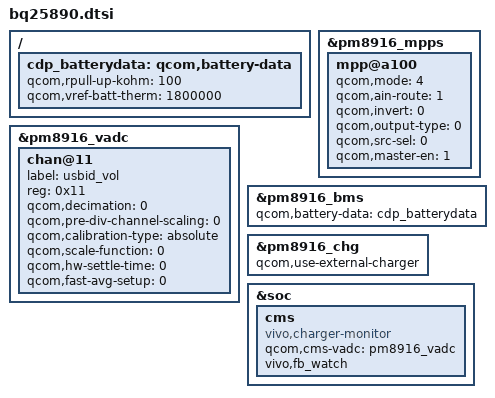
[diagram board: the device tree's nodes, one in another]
/* Copyright (c) 2014, The Linux Foundation. All rights reserved.
*
* This program is free software; you can redistribute it and/or modify
* it under the terms of the GNU General Public License version 2 and
* only version 2 as published by the Free Software Foundation.
*
* This program is distributed in the hope that it will be useful,
* but WITHOUT ANY WARRANTY; without even the implied warranty of
* MERCHANTABILITY or FITNESS FOR A PARTICULAR PURPOSE.  See the
* GNU General Public License for more details.
*/
&pm8916_mpps{
	mpp@a100 {
		qcom,mode = <4>;
		qcom,ain-route = <1>;
		qcom,invert = <0>; //No Invert
		qcom,output-type = <0>; //CMOS
		qcom,src-sel = <0>;
		qcom,master-en = <1>;
		status = "ok";
	};
};
&pm8916_vadc{
	chan@11 {
		label = "usbid_vol";
		reg = <0x11>;
		qcom,decimation = <0>;
		qcom,pre-div-channel-scaling = <0>;
		qcom,calibration-type = "absolute";
		qcom,scale-function = <0>;
		qcom,hw-settle-time = <0>;
		qcom,fast-avg-setup = <0>;
	};
};

/ {
	cdp_batterydata: qcom,battery-data {
		qcom,rpull-up-kohm = <100>;
		qcom,vref-batt-therm = <1800000>;
	};
};

&pm8916_bms {
	status = "ok";
	qcom,battery-data = <&cdp_batterydata>;
};

&pm8916_chg {
	status = "ok";
	qcom,use-external-charger;
};

&soc {
	cms{
		compatible = "vivo,charger-monitor";
		qcom,cms-vadc = <&pm8916_vadc>;
		vivo,fb_watch;
	};
};

